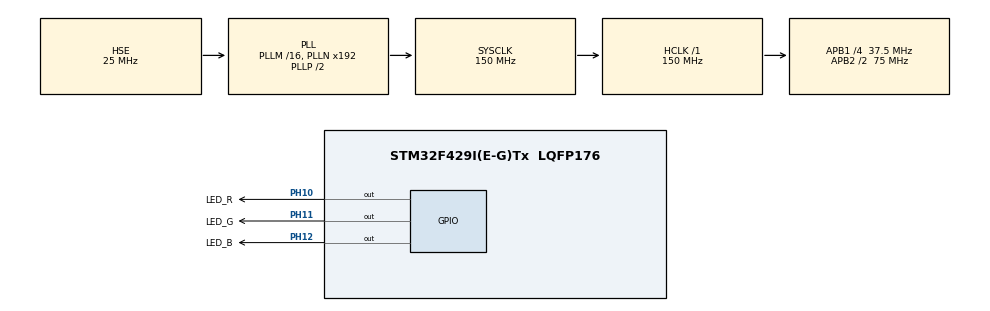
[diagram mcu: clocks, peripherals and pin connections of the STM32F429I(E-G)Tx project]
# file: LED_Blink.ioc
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Mcu.Family=STM32F4
Mcu.Name=STM32F429I(E-G)Tx
Mcu.Package=LQFP176
NVIC.PriorityGroup=NVIC_PRIORITYGROUP_4
PA13.Mode=Serial_Wire
PA13.Signal=SYS_JTMS-SWDIO
PA14.Mode=Serial_Wire
PA14.Signal=SYS_JTCK-SWCLK
PC14/OSC32_IN.Mode=LSE-External-Oscillator
PC14/OSC32_IN.Signal=RCC_OSC32_IN
PC15/OSC32_OUT.Mode=LSE-External-Oscillator
PC15/OSC32_OUT.Signal=RCC_OSC32_OUT
PH0/OSC_IN.Mode=HSE-External-Oscillator
PH0/OSC_IN.Signal=RCC_OSC_IN
PH1/OSC_OUT.Mode=HSE-External-Oscillator
PH1/OSC_OUT.Signal=RCC_OSC_OUT
PH10.GPIO_Label=LED_R
PH10.PinState=GPIO_PIN_SET
PH10.Signal=GPIO_Output
PH11.GPIO_Label=LED_G
PH11.PinState=GPIO_PIN_SET
PH11.Signal=GPIO_Output
PH12.GPIO_Label=LED_B
PH12.PinState=GPIO_PIN_SET
PH12.Signal=GPIO_Output
ProjectManager.HeapSize=0x200
ProjectManager.StackSize=0x400
ProjectManager.TargetToolchain=MDK-ARM V5.32
RCC.48MHZClocksFreq_Value=75000000
RCC.AHBFreq_Value=150000000
RCC.APB1CLKDivider=RCC_HCLK_DIV4
RCC.APB1Freq_Value=37500000
RCC.APB1TimFreq_Value=75000000
RCC.APB2CLKDivider=RCC_HCLK_DIV2
RCC.APB2Freq_Value=75000000
RCC.APB2TimFreq_Value=150000000
RCC.CortexFreq_Value=150000000
RCC.HCLKFreq_Value=150000000
RCC.HSE_VALUE=25000000
RCC.HSI_VALUE=16000000
RCC.PLLSourceVirtual=RCC_PLLSOURCE_HSE
RCC.SYSCLKFreq_VALUE=150000000
RCC.SYSCLKSource=RCC_SYSCLKSOURCE_PLLCLK
RCC.VCOOutputFreq_Value=300000000
board=custom

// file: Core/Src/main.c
/* USER CODE BEGIN Header */
/**
  ******************************************************************************
  * @file           : main.c
  * @brief          : Main program body
  ******************************************************************************
  * @attention
  *
  * Copyright (c) 2026 STMicroelectronics.
  * All rights reserved.
  *
  * This software is licensed under terms that can be found in the LICENSE file
  * in the root directory of this software component.
  * If no LICENSE file comes with this software, it is provided AS-IS.
  *
  ******************************************************************************
  */
/* USER CODE END Header */
#include "main.h"

void SystemClock_Config(void);
static void MX_GPIO_Init(void);

int main(void)
{

  /* USER CODE BEGIN 1 */
	// Make sure exceptions use this application's vector table.
  SCB->VTOR = FLASH_BASE;
  /* USER CODE END 1 */

  /* MCU Configuration--------------------------------------------------------*/

  /* Reset of all peripherals, Initializes the Flash interface and the Systick. */
  HAL_Init();

  /* Configure the system clock */
  SystemClock_Config();

  /* Initialize all configured peripherals */
  MX_GPIO_Init();

  /* Infinite loop */
  /* USER CODE BEGIN WHILE */
  while (1)
  {
		HAL_GPIO_WritePin(GPIOH, LED_B_Pin, GPIO_PIN_SET);		// Set GPIO state to high.
    HAL_GPIO_WritePin(GPIOH, LED_R_Pin, GPIO_PIN_RESET);	// Set GPIO state to low.
		HAL_Delay(500);		// Delay 500 milliseconds.

		HAL_GPIO_WritePin(GPIOH, LED_R_Pin, GPIO_PIN_SET);
		HAL_GPIO_WritePin(GPIOH, LED_G_Pin, GPIO_PIN_RESET);
		HAL_Delay(500);

		HAL_GPIO_WritePin(GPIOH, LED_G_Pin, GPIO_PIN_SET);
		HAL_GPIO_WritePin(GPIOH, LED_B_Pin, GPIO_PIN_RESET);
		HAL_Delay(500);

    /* USER CODE END WHILE */

  }
}

void SystemClock_Config(void)
{
  RCC_OscInitTypeDef RCC_OscInitStruct = {0};
  RCC_ClkInitTypeDef RCC_ClkInitStruct = {0};

  /** Configure the main internal regulator output voltage
  */
  __HAL_RCC_PWR_CLK_ENABLE();
  __HAL_PWR_VOLTAGESCALING_CONFIG(PWR_REGULATOR_VOLTAGE_SCALE1);

  /** Initializes the RCC Oscillators according to the specified parameters
  * in the RCC_OscInitTypeDef structure.
  */
  /* This project assumes a real 25 MHz HSE source on PH0/PH1. */
  RCC_OscInitStruct.OscillatorType = RCC_OSCILLATORTYPE_HSE;
  RCC_OscInitStruct.HSEState = RCC_HSE_ON;
  RCC_OscInitStruct.PLL.PLLState = RCC_PLL_ON;
  RCC_OscInitStruct.PLL.PLLSource = RCC_PLLSOURCE_HSE;
  RCC_OscInitStruct.PLL.PLLM = 16;
  RCC_OscInitStruct.PLL.PLLN = 192;
  RCC_OscInitStruct.PLL.PLLP = RCC_PLLP_DIV2;
  RCC_OscInitStruct.PLL.PLLQ = 4;
  if (HAL_RCC_OscConfig(&RCC_OscInitStruct) != HAL_OK)
  {
    Error_Handler();
  }

  /** Initializes the CPU, AHB and APB buses clocks
  */
  RCC_ClkInitStruct.ClockType = RCC_CLOCKTYPE_HCLK|RCC_CLOCKTYPE_SYSCLK
                              |RCC_CLOCKTYPE_PCLK1|RCC_CLOCKTYPE_PCLK2;
  RCC_ClkInitStruct.SYSCLKSource = RCC_SYSCLKSOURCE_PLLCLK;
  RCC_ClkInitStruct.AHBCLKDivider = RCC_SYSCLK_DIV1;
  RCC_ClkInitStruct.APB1CLKDivider = RCC_HCLK_DIV4;
  RCC_ClkInitStruct.APB2CLKDivider = RCC_HCLK_DIV2;

  if (HAL_RCC_ClockConfig(&RCC_ClkInitStruct, FLASH_LATENCY_4) != HAL_OK)
  {
    Error_Handler();
  }
}

static void MX_GPIO_Init(void)
{
  GPIO_InitTypeDef GPIO_InitStruct = {0};

  /* GPIO Ports Clock Enable */
  __HAL_RCC_GPIOC_CLK_ENABLE();
  __HAL_RCC_GPIOH_CLK_ENABLE();
  __HAL_RCC_GPIOA_CLK_ENABLE();

  /*Configure GPIO pin Output Level */
  HAL_GPIO_WritePin(GPIOH, LED_R_Pin|LED_G_Pin|LED_B_Pin, GPIO_PIN_SET);

  /*Configure GPIO pins : LED_R_Pin LED_G_Pin LED_B_Pin */
  GPIO_InitStruct.Pin = LED_R_Pin|LED_G_Pin|LED_B_Pin;
  GPIO_InitStruct.Mode = GPIO_MODE_OUTPUT_PP;
  GPIO_InitStruct.Pull = GPIO_NOPULL;
  GPIO_InitStruct.Speed = GPIO_SPEED_FREQ_LOW;
  HAL_GPIO_Init(GPIOH, &GPIO_InitStruct);

}

void Error_Handler(void)
{
  __disable_irq();
  while (1)
  {
  }
}
